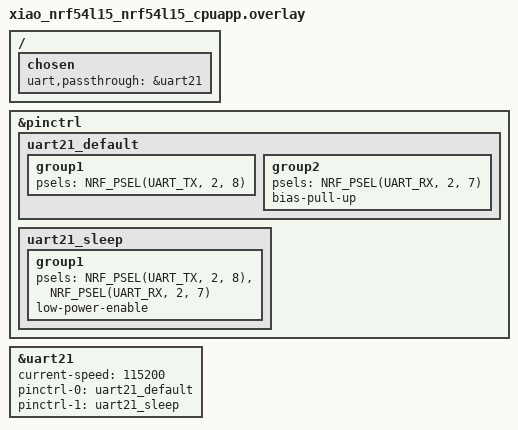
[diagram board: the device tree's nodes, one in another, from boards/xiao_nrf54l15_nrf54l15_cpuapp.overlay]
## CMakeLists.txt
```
# SPDX-License-Identifier: Apache-2.0

cmake_minimum_required(VERSION 3.20)

find_package(Zephyr REQUIRED HINTS $ENV{ZEPHYR_BASE})
project(xiao_nrf54l15_uart_test)

target_sources(app PRIVATE src/main.c)
```

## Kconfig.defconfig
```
# Fix for xiao_nrf54l15 BT_CTLR Kconfig warning
# The board's Kconfig.defconfig defines BT_CTLR without a type.
# This file is loaded before the board's defconfig, so we can properly define it here.

if BOARD_XIAO_NRF54L15_NRF54L15_CPUAPP

# Properly define BT_CTLR with type before the board's defconfig loads
config BT_CTLR
	bool
	default BT

endif
```

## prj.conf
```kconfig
# CONFIG_UART_INTERRUPT_DRIVEN=y

# CONFIG_SERIAL=y
```

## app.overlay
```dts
/ {
	chosen {
		ncs,dtm-uart = &uart20;
	};
};

/* uart20 is USB CDC, already configured in board dts with status = "okay" */
```

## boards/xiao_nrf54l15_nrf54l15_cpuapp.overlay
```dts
/*
 * XIAO nRF54L15 UART21 设备树配置
 *
 * 引脚:
 *   TX: P2.08 (D6)
 *   RX: P2.07 (D7)
 */

/ {
	chosen {
		uart,passthrough = &uart21;
	};
};

&pinctrl {
	uart21_default: uart21_default {
		group1 {
			psels = <NRF_PSEL(UART_TX, 2, 8)>;
		};
		group2 {
			psels = <NRF_PSEL(UART_RX, 2, 7)>;
			bias-pull-up;
		};
	};

	uart21_sleep: uart21_sleep {
		group1 {
			psels = <NRF_PSEL(UART_TX, 2, 8)>,
				<NRF_PSEL(UART_RX, 2, 7)>;
			low-power-enable;
		};
	};
};

&uart21 {
	current-speed = <115200>;
	pinctrl-0 = <&uart21_default>;
	pinctrl-1 = <&uart21_sleep>;
	pinctrl-names = "default", "sleep";
	status = "okay";
};
```

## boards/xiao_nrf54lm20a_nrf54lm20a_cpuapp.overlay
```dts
/*
 * Copyright (c) 2026
 *
 * SPDX-License-Identifier: LicenseRef-Nordic-5-Clause
 */

/ {
	chosen {
		ncs,dtm-uart = &uart20;
	};
};

&radio {
	/* XIAO board configuration does not provide the antenna matrix
	 * properties required by the DTM direction finding path.
	 */
	/delete-property/ dfe-supported;
};
```

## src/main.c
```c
/**
 * @file main.c
 * @brief BMM150 磁力计数据通过 ESP8266 MQTT 上传到 OneNET
 * STM32F103C8T6 @ 72MHz (HAL库)
 */

#include "stm32f1xx_hal.h"
#include "esp8266.h"
#include "onenet.h"
#include "mqttkit.h"
#include "bmm150.h"
#include "bmm150_platform.h"
#include "gps.h"
#include <stdio.h>
#include <string.h>

/* I2C和UART句柄 */
I2C_HandleTypeDef hi2c1;
UART_HandleTypeDef huart1;
UART_HandleTypeDef huart2;
UART_HandleTypeDef huart3;

/* ESP8266接收缓冲区 */
unsigned char esp8266_buf[512];
unsigned short esp8266_cnt = 0;

/* BMM150设备句柄和数据 */
bmm150_dev_t bmm150_dev;
bmm150_data_t bmm150_data;

/* BMM150全局数据 - 供onenet.c通过extern引用 */
int16_t bmm_x = 0;
int16_t bmm_y = 0;
int16_t bmm_z = 0;

/* 72MHz时钟配置 */
void SystemClock_Config(void)
{
    RCC_OscInitTypeDef osc = {0};
    RCC_ClkInitTypeDef clk = {0};

    osc.OscillatorType = RCC_OSCILLATORTYPE_HSE;
    osc.HSEState = RCC_HSE_ON;
    osc.PLL.PLLState = RCC_PLL_ON;
    osc.PLL.PLLSource = RCC_PLLSOURCE_HSE;
    osc.PLL.PLLMUL = RCC_PLL_MUL9;
    HAL_RCC_OscConfig(&osc);

    clk.ClockType = RCC_CLOCKTYPE_HCLK | RCC_CLOCKTYPE_SYSCLK |
                    RCC_CLOCKTYPE_PCLK1 | RCC_CLOCKTYPE_PCLK2;
    clk.SYSCLKSource = RCC_SYSCLKSOURCE_PLLCLK;
    clk.AHBCLKDivider = RCC_SYSCLK_DIV1;
    clk.APB1CLKDivider = RCC_HCLK_DIV2;
    clk.APB2CLKDivider = RCC_HCLK_DIV1;
    HAL_RCC_ClockConfig(&clk, FLASH_LATENCY_2);
}

/* USART1初始化 (调试输出) - PA9 TX, PA10 RX */
void USART1_Init(void)
{
    __HAL_RCC_USART1_CLK_ENABLE();
    __HAL_RCC_GPIOA_CLK_ENABLE();

    GPIO_InitTypeDef gpio = {0};

    /* PA9 TX */
    gpio.Pin = GPIO_PIN_9;
    gpio.Mode = GPIO_MODE_AF_PP;
    gpio.Speed = GPIO_SPEED_FREQ_HIGH;
    HAL_GPIO_Init(GPIOA, &gpio);

    /* PA10 RX */
    gpio.Pin = GPIO_PIN_10;
    gpio.Mode = GPIO_MODE_INPUT;
    gpio.Pull = GPIO_PULLUP;
    HAL_GPIO_Init(GPIOA, &gpio);

    /* 使用HAL库初始化USART1 */
    huart1.Instance = USART1;
    huart1.Init.BaudRate = 115200;
    huart1.Init.WordLength = UART_WORDLENGTH_8B;
    huart1.Init.StopBits = UART_STOPBITS_1;
    huart1.Init.Parity = UART_PARITY_NONE;
    huart1.Init.Mode = UART_MODE_TX_RX;
    huart1.Init.HwFlowCtl = UART_HWCONTROL_NONE;
    huart1.Init.OverSampling = UART_OVERSAMPLING_16;
    HAL_UART_Init(&huart1);
}

/* USART2初始化 (ESP8266通信) */
void USART2_Init(void)
{
    __HAL_RCC_USART2_CLK_ENABLE();
    __HAL_RCC_GPIOA_CLK_ENABLE();

    GPIO_InitTypeDef gpio = {0};
    gpio.Pin = GPIO_PIN_2;  /* TX */
    gpio.Mode = GPIO_MODE_AF_PP;
    gpio.Speed = GPIO_SPEED_FREQ_HIGH;
    HAL_GPIO_Init(GPIOA, &gpio);

    gpio.Pin = GPIO_PIN_3;  /* RX */
    gpio.Mode = GPIO_MODE_INPUT;
    gpio.Pull = GPIO_PULLUP;
    HAL_GPIO_Init(GPIOA, &gpio);

    huart2.Instance = USART2;
    huart2.Init.BaudRate = 115200;
    huart2.Init.WordLength = UART_WORDLENGTH_8B;
    huart2.Init.StopBits = UART_STOPBITS_1;
    huart2.Init.Parity = UART_PARITY_NONE;
    huart2.Init.Mode = UART_MODE_TX_RX;
    huart2.Init.HwFlowCtl = UART_HWCONTROL_NONE;
    huart2.Init.OverSampling = UART_OVERSAMPLING_16;
    HAL_UART_Init(&huart2);

    HAL_NVIC_SetPriority(USART2_IRQn, 0, 0);
    HAL_NVIC_EnableIRQ(USART2_IRQn);
    __HAL_UART_ENABLE_IT(&huart2, UART_IT_RXNE);
}

/* USART2中断接收 (ESP8266) */
void USART2_IRQHandler(void)
{
    if(__HAL_UART_GET_FLAG(&huart2, UART_FLAG_RXNE) != RESET)
    {
        if(esp8266_cnt >= sizeof(esp8266_buf))
            esp8266_cnt = 0;

        esp8266_buf[esp8266_cnt++] = (uint8_t)(huart2.Instance->DR & 0xFF);
        __HAL_UART_CLEAR_FLAG(&huart2, UART_FLAG_RXNE);
    }
}

/* I2C1初始化 (BMM150通信) - PB6 SCL, PB7 SDA */
void I2C1_Init(void)
{
    __HAL_RCC_I2C1_CLK_ENABLE();
    __HAL_RCC_GPIOB_CLK_ENABLE();

    GPIO_InitTypeDef gpio = {0};

    /* PB6 SCL, PB7 SDA */
    gpio.Pin = GPIO_PIN_6 | GPIO_PIN_7;
    gpio.Mode = GPIO_MODE_AF_OD;
    gpio.Speed = GPIO_SPEED_FREQ_HIGH;
    gpio.Pull = GPIO_PULLUP;
    HAL_GPIO_Init(GPIOB, &gpio);

    /* I2C1配置 */
    hi2c1.Instance = I2C1;
    hi2c1.Init.ClockSpeed = 100000;  /* 100kHz */
    hi2c1.Init.DutyCycle = I2C_DUTYCYCLE_2;
    hi2c1.Init.OwnAddress1 = 0;
    hi2c1.Init.AddressingMode = I2C_ADDRESSINGMODE_7BIT;
    hi2c1.Init.DualAddressMode = I2C_DUALADDRESS_DISABLE;
    hi2c1.Init.OwnAddress2 = 0;
    hi2c1.Init.GeneralCallMode = I2C_GENERALCALL_DISABLE;
    hi2c1.Init.NoStretchMode = I2C_NOSTRETCH_DISABLE;
    HAL_I2C_Init(&hi2c1);
}

/* I2C总线扫描 - 查找连接的设备 */
void I2C_Scan(void)
{
    char buf[50];
    UART1_SendString("Scanning I2C bus...\r\n");

    for (uint8_t addr = 0; addr < 128; addr++) {
        if (HAL_I2C_IsDeviceReady(&hi2c1, (uint16_t)(addr << 1), 1, 10) == HAL_OK) {
            sprintf(buf, "Found device at 0x%02X (7-bit: 0x%02X)\r\n", addr << 1, addr);
            UART1_SendString(buf);
        }
    }
    UART1_SendString("Scan complete.\r\n");
}

/* 简单串口发送函数 */
void UART1_SendString(const char *str)
{
    HAL_UART_Transmit(&huart1, (uint8_t*)str, strlen(str), 1000);
}

/* 全局调试打印函数 - 供其他模块调用 */
void DebugPrint(const char *str)
{
    UART1_SendString(str);
}

int main(void)
{
    HAL_Init();
    SystemClock_Config();

    /* LED PC13 */
    __HAL_RCC_GPIOC_CLK_ENABLE();
    GPIO_InitTypeDef led = {0};
    led.Pin = GPIO_PIN_13;
    led.Mode = GPIO_MODE_OUTPUT_PP;
    led.Speed = GPIO_SPEED_FREQ_LOW;
    HAL_GPIO_Init(GPIOC, &led);

    /* 初始化USART1 */
    USART1_Init();

    /* 立即发送测试数据 - 不依赖其他初始化 */
    UART1_SendString("USART1 Test OK!\r\n");
    HAL_Delay(100);
    UART1_SendString("System Init...\r\n");
    HAL_Delay(100);

    /* 初始化USART2 */
    USART2_Init();
    UART1_SendString("USART2 Init OK\r\n");

    /* 初始化I2C1 */
    I2C1_Init();
    UART1_SendString("I2C1 Init OK\r\n");

    /* 初始化GPS */
    GPS_Init();
    UART1_SendString("GPS Init OK\r\n");

    /* 扫描I2C总线，查找BMM150 */
    I2C_Scan();

    /* 初始化BMM150 */
    char msg_buf[100];
    UART1_SendString("Initializing BMM150...\r\n");

    /* 步骤1: 唤醒BMM150 - 写入0x01到电源控制寄存器0x4B */
    uint8_t pwr_cmd = 0x01;
    HAL_I2C_Mem_Write(&hi2c1, (BMM150_DEFAULT_I2C_ADDRESS << 1), 0x4B, I2C_MEMADD_SIZE_8BIT, &pwr_cmd, 1, 100);
    HAL_Delay(10);  /* 等待唤醒 */

    /* 步骤2: 再次读取Chip ID */
    uint8_t chip_id = 0;
    HAL_I2C_Mem_Read(&hi2c1, (BMM150_DEFAULT_I2C_ADDRESS << 1), 0x40, I2C_MEMADD_SIZE_8BIT, &chip_id, 1, 100);
    sprintf(msg_buf, "Chip ID after wake: 0x%02X (expected: 0x32)\r\n", chip_id);
    UART1_SendString(msg_buf);

    bmm150_status_t status = bmm150_init(&bmm150_dev, BMM150_DEFAULT_I2C_ADDRESS);
    if (status != BMM150_OK) {
        sprintf(msg_buf, "BMM150 Init FAILED! Error: %d\r\n", status);
        UART1_SendString(msg_buf);
        while (1) {
            HAL_GPIO_TogglePin(GPIOC, GPIO_PIN_13);
            HAL_Delay(100);
        }
    }
    UART1_SendString("BMM150 Init OK\r\n");

    UART1_SendString("\r\n=================================\r\n");
    UART1_SendString("STM32F103C8T6 @ 72MHz\r\n");
    UART1_SendString("BMM150 + ESP8266 MQTT\r\n");
    UART1_SendString("=================================\r\n\r\n");

    /* 初始化ESP8266并连接MQTT */
    UART1_SendString("Initializing ESP8266...\r\n");
    ESP8266_Init();

    UART1_SendString("\r\nConnecting to MQTT...\r\n");
    if (OneNet_DevLink() != 0) {
        UART1_SendString("MQTT Connect FAILED!\r\n");
        while (1) {
            HAL_GPIO_TogglePin(GPIOC, GPIO_PIN_13);
            HAL_Delay(100);
        }
    }

    /* 订阅主题 */
    OneNET_Subscribe();

    UART1_SendString("\r\nStart reading BMM150 sensor data...\r\n\r\n");

    uint32_t count = 0;

    while (1) {
        /* 从BMM150读取真实传感器数据 */
        status = bmm150_get_mag_data(&bmm150_dev, &bmm150_data);
        if (status == BMM150_OK) {
            bmm_x = (int16_t)bmm150_data.x;
            bmm_y = (int16_t)bmm150_data.y;
            bmm_z = (int16_t)bmm150_data.z;

            sprintf(msg_buf, "[%lu] X:%d Y:%d Z:%d (%.1f %.1f %.1f uT)\r\n",
                    count, bmm_x, bmm_y, bmm_z,
                    bmm150_data.x_uT, bmm150_data.y_uT, bmm150_data.z_uT);
            UART1_SendString(msg_buf);
        } else {
            sprintf(msg_buf, "[%lu] BMM150 read error: %d\r\n", count, status);
            UART1_SendString(msg_buf);
        }

        /* 显示GPS数据 */
        gps_data_t *gps = GPS_GetData();
        sprintf(msg_buf, "GPS: lat=%ld, lon=%ld, sats=%d, valid=%d\r\n",
                gps->latitude, gps->longitude, gps->sat_count, gps->valid);
        UART1_SendString(msg_buf);

        /* 发送到MQTT */
        OneNet_SendData();

        /* LED闪烁 */
        HAL_GPIO_TogglePin(GPIOC, GPIO_PIN_13);
        count++;

        /* 检查接收数据 */
        unsigned char *dataPtr = ESP8266_GetIPD(50);
        if (dataPtr != NULL) {
            OneNet_RevPro(dataPtr);
        }

        /* 定时发送心跳 */
        if (count % 30 == 0) {
            MQTT_Ping();
        }

        HAL_Delay(1000);
    }
}
```

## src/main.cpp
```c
#include <Arduino.h>

// PB02: Control pin - pull HIGH to enable voltage reading
// PB03: ADC input (AIN11)
// Reference: INTVCC1 (VDDANA/2), Gain: DIV2 -> Full scale = 3.3V

#define ADC_FULL_SCALE 4095.0f

static void adc_init(void) {
    // Enable ADC bus clock
    PM->APBCMASK.reg |= PM_APBCMASK_ADC;

    // Feed GCLK0 to ADC
    GCLK->CLKCTRL.reg = GCLK_CLKCTRL_ID_ADC |
                         GCLK_CLKCTRL_GEN_GCLK0 |
                         GCLK_CLKCTRL_CLKEN;
    while (GCLK->STATUS.bit.SYNCBUSY);

    // Reset ADC
    ADC->CTRLA.bit.SWRST = 1;
    while (ADC->CTRLA.bit.SWRST);

    // Reference: INTVCC1 = VDDANA / 2 (~1.65V)
    ADC->REFCTRL.reg = ADC_REFCTRL_REFSEL_INTVCC1;

    // No averaging
    ADC->AVGCTRL.reg = ADC_AVGCTRL_SAMPLENUM_1;

    // 12-bit resolution, prescaler DIV32 (48MHz/32 = 1.5MHz)
    ADC->CTRLB.reg = ADC_CTRLB_RESSEL_12BIT |
                     ADC_CTRLB_PRESCALER_DIV32;
    while (ADC->STATUS.bit.SYNCBUSY);

    // Positive input: AIN11 (PB03), Negative: GND, Gain: DIV2
    // DIV2 gain + 1.65V ref = 3.3V full scale
    ADC->INPUTCTRL.reg = ADC_INPUTCTRL_MUXPOS_PIN11 |
                         ADC_INPUTCTRL_MUXNEG_GND |
                         ADC_INPUTCTRL_GAIN_DIV2;
    while (ADC->STATUS.bit.SYNCBUSY);

    // Enable ADC
    ADC->CTRLA.bit.ENABLE = 1;
    while (ADC->STATUS.bit.SYNCBUSY);
}

static uint16_t adc_read(void) {
    ADC->SWTRIG.bit.START = 1;
    while (ADC->STATUS.bit.SYNCBUSY);
    while (!ADC->INTFLAG.bit.RESRDY);
    return ADC->RESULT.reg;
}

void setup() {
    Serial1.begin(230400);
    delay(100);

    Serial1.println("============================================");
    Serial1.println("  ADC Voltage Reader - XIAO SAMD21");
    Serial1.println("  ADC Pin: PB03 (AIN11)");
    Serial1.println("  Control: PB02 (HIGH to enable reading)");
    Serial1.println("============================================");

    // PB02: GPIO output, pull HIGH and keep
    PORT->Group[1].DIRSET.reg = PORT_PB02;
    PORT->Group[1].OUTSET.reg = PORT_PB02;
    delay(1);  // Wait for voltage to settle

    // PB03: analog input via peripheral mux
    PORT->Group[1].PINCFG[3].bit.PMUXEN = 1;   // Enable PMUX
    PORT->Group[1].PINCFG[3].bit.INEN   = 0;   // Disable digital input buffer
    PORT->Group[1].PINCFG[3].bit.PULLEN = 0;   // No pull resistor
    // PB03 is odd pin -> uses PMUX[1].PMUXO, function B = Analog
    PORT->Group[1].PMUX[1].bit.PMUXO = PORT_PMUX_PMUXO_B_Val;

    adc_init();
    Serial1.println("ADC initialized, starting readings...\n");
}

void loop() {
    uint16_t raw = adc_read();

    // Voltage = raw * (1.65V * 2) / 4095 = raw * 3.3 / 4095
    float voltage = (raw * 3.3f) / ADC_FULL_SCALE;

    Serial1.print("Raw: ");
    Serial1.print(raw);
    Serial1.print("  Voltage: ");
    Serial1.print(voltage, 3);
    Serial1.println(" V");

    delay(1000);
}
```

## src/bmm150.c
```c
/**
 * @file bmm150.c
 * @brief BMM150 三轴地磁传感器驱动实现
 */

#include <stdint.h>
#include <stddef.h>
#include "bmm150.h"
#include "bmm150_platform.h"

/* 校准数据掩码和位置 */
#define BMM150_TRIM_XLSB_MASK       0x7F
#define BMM150_TRIM_YLSB_MASK       0x7F
#define BMM150_TRIM_ZLSB_MASK       0x7F
#define BMM150_TRIM_XYLSB_SHIFT     7

/* 校准系数 */
#define BMM150_LSB_TO_UT_FACTOR     16.0f   /* LSB到微特斯拉转换因子 */

/* 内部函数声明 */
static bmm150_status_t read_trim_data(bmm150_dev_t *dev);
static int16_t compensate_x(int16_t raw_x, bmm150_dev_t *dev);
static int16_t compensate_y(int16_t raw_y, bmm150_dev_t *dev);
static int16_t compensate_z(int16_t raw_z, bmm150_dev_t *dev);

/**
 * @brief 初始化BMM150传感器
 */
bmm150_status_t bmm150_init(bmm150_dev_t *dev, uint8_t i2c_addr)
{
    uint8_t chip_id = 0;
    bmm150_status_t status;

    if (dev == NULL) {
        return BMM150_E_NULL_PTR;
    }

    dev->i2c_addr = i2c_addr;

    /* 检查设备是否存在 */
    status = bmm150_get_chip_id(dev, &chip_id);
    if (status != BMM150_OK) {
        return status;
    }

    if (chip_id != BMM150_CHIP_ID) {
        return BMM150_E_DEV_NOT_FOUND;
    }

    /* 设置默认配置 - 不执行软复位，直接配置 */
    dev->config.op_mode = BMM150_NORMAL_MODE;
    dev->config.data_rate = BMM150_DATA_RATE_10HZ;
    dev->config.xy_rep = BMM150_REPXY_REGULAR;
    dev->config.z_rep = BMM150_REPZ_REGULAR;

    /* 写入默认配置 */
    bmm150_set_data_rate(dev, dev->config.data_rate);
    bmm150_set_xy_rep(dev, dev->config.xy_rep);
    bmm150_set_z_rep(dev, dev->config.z_rep);
    bmm150_set_op_mode(dev, dev->config.op_mode);

    /* 读取校准数据 */
    status = read_trim_data(dev);
    if (status != BMM150_OK) {
        return status;
    }

    return BMM150_OK;
}

/**
 * @brief 软复位传感器
 */
bmm150_status_t bmm150_soft_reset(bmm150_dev_t *dev)
{
    uint8_t reg_data;
    bmm150_status_t status;

    if (dev == NULL) {
        return BMM150_E_NULL_PTR;
    }

    /* 写入软复位命令 */
    reg_data = BMM150_POWER_CNTRL_SOFT_RESET;
    status = bmm150_write_reg(dev, BMM150_POWER_CONTROL_REG, &reg_data, 1);
    if (status != BMM150_OK) {
        return status;
    }

    /* 等待复位完成 */
    bmm150_delay_ms(2);

    /* 检查复位是否完成 */
    do {
        status = bmm150_read_reg(dev, BMM150_POWER_CONTROL_REG, &reg_data, 1);
        if (status != BMM150_OK) {
            return status;
        }
    } while (reg_data & BMM150_POWER_CNTRL_SOFT_RESET);

    return BMM150_OK;
}

/**
 * @brief 设置操作模式
 */
bmm150_status_t bmm150_set_op_mode(bmm150_dev_t *dev, uint8_t op_mode)
{
    uint8_t reg_data;
    bmm150_status_t status;

    if (dev == NULL) {
        return BMM150_E_NULL_PTR;
    }

    status = bmm150_read_reg(dev, BMM150_OP_MODE_REG, &reg_data, 1);
    if (status != BMM150_OK) {
        return status;
    }

    reg_data = (reg_data & 0xE1) | (op_mode & 0x1E);

    status = bmm150_write_reg(dev, BMM150_OP_MODE_REG, &reg_data, 1);
    if (status == BMM150_OK) {
        dev->config.op_mode = op_mode;
    }

    return status;
}

/**
 * @brief 设置数据输出速率
 */
bmm150_status_t bmm150_set_data_rate(bmm150_dev_t *dev, uint8_t data_rate)
{
    uint8_t reg_data;
    bmm150_status_t status;

    if (dev == NULL) {
        return BMM150_E_NULL_PTR;
    }

    status = bmm150_read_reg(dev, BMM150_OP_MODE_REG, &reg_data, 1);
    if (status != BMM150_OK) {
        return status;
    }

    reg_data = (reg_data & 0x1F) | ((data_rate << 3) & 0xE0);

    status = bmm150_write_reg(dev, BMM150_OP_MODE_REG, &reg_data, 1);
    if (status == BMM150_OK) {
        dev->config.data_rate = data_rate;
    }

    return status;
}

/**
 * @brief 设置XY轴重复次数
 */
bmm150_status_t bmm150_set_xy_rep(bmm150_dev_t *dev, uint8_t rep_xy)
{
    bmm150_status_t status;

    if (dev == NULL) {
        return BMM150_E_NULL_PTR;
    }

    status = bmm150_write_reg(dev, BMM150_REP_XY_REG, &rep_xy, 1);
    if (status == BMM150_OK) {
        dev->config.xy_rep = rep_xy;
    }

    return status;
}

/**
 * @brief 设置Z轴重复次数
 */
bmm150_status_t bmm150_set_z_rep(bmm150_dev_t *dev, uint8_t rep_z)
{
    bmm150_status_t status;

    if (dev == NULL) {
        return BMM150_E_NULL_PTR;
    }

    status = bmm150_write_reg(dev, BMM150_REP_Z_REG, &rep_z, 1);
    if (status == BMM150_OK) {
        dev->config.z_rep = rep_z;
    }

    return status;
}

/**
 * @brief 检查数据是否就绪
 */
uint8_t bmm150_is_data_ready(bmm150_dev_t *dev)
{
    uint8_t reg_data;

    if (dev == NULL) {
        return 0;
    }

    if (bmm150_read_reg(dev, BMM150_DATA_READY_STATUS, &reg_data, 1) != BMM150_OK) {
        return 0;
    }

    return (reg_data & 0x01);
}

/**
 * @brief 获取原始磁力数据
 */
bmm150_status_t bmm150_get_raw_data(bmm150_dev_t *dev, bmm150_data_t *data)
{
    uint8_t buffer[8];
    bmm150_status_t status;

    if (dev == NULL || data == NULL) {
        return BMM150_E_NULL_PTR;
    }

    /* 如果是强制模式，需要先触发测量 */
    if (dev->config.op_mode == BMM150_FORCED_MODE) {
        status = bmm150_set_op_mode(dev, BMM150_FORCED_MODE);
        if (status != BMM150_OK) {
            return status;
        }
        /* 等待数据就绪 */
        while (!bmm150_is_data_ready(dev)) {
            bmm150_delay_ms(1);
        }
    }

    /* 读取数据寄存器 (0x42-0x48) */
    status = bmm150_read_reg(dev, BMM150_DATA_X_LSB, buffer, 8);
    if (status != BMM150_OK) {
        return status;
    }

    /* 解析X轴数据 (13位, 有符号) */
    data->x = (int16_t)(((uint16_t)buffer[1] << 8) | (buffer[0] & 0xF8));
    data->x = data->x >> 3;

    /* 解析Y轴数据 (13位, 有符号) */
    data->y = (int16_t)(((uint16_t)buffer[3] << 8) | (buffer[2] & 0xF8));
    data->y = data->y >> 3;

    /* 解析Z轴数据 (15位, 有符号) */
    data->z = (int16_t)(((uint16_t)buffer[5] << 8) | (buffer[4] & 0xFE));
    data->z = data->z >> 1;

    /* 数据就绪状态 */
    data->data_ready = buffer[7] & 0x01;

    return BMM150_OK;
}

/**
 * @brief 获取转换后的磁力数据(微特斯拉)
 */
bmm150_status_t bmm150_get_mag_data(bmm150_dev_t *dev, bmm150_data_t *data)
{
    bmm150_status_t status;
    int16_t compensated_x, compensated_y, compensated_z;

    if (dev == NULL || data == NULL) {
        return BMM150_E_NULL_PTR;
    }

    /* 获取原始数据 */
    status = bmm150_get_raw_data(dev, data);
    if (status != BMM150_OK) {
        return status;
    }

    /* 应用补偿 */
    compensated_x = compensate_x(data->x, dev);
    compensated_y = compensate_y(data->y, dev);
    compensated_z = compensate_z(data->z, dev);

    /* 转换为微特斯拉 */
    data->x_uT = (float)compensated_x * BMM150_LSB_TO_UT_FACTOR / 1000.0f;
    data->y_uT = (float)compensated_y * BMM150_LSB_TO_UT_FACTOR / 1000.0f;
    data->z_uT = (float)compensated_z * BMM150_LSB_TO_UT_FACTOR / 1000.0f;

    return BMM150_OK;
}

/**
 * @brief 读取芯片ID
 */
bmm150_status_t bmm150_get_chip_id(bmm150_dev_t *dev, uint8_t *chip_id)
{
    if (dev == NULL || chip_id == NULL) {
        return BMM150_E_NULL_PTR;
    }

    return bmm150_read_reg(dev, BMM150_CHIP_ID_REG, chip_id, 1);
}

/**
 * @brief 执行自检
 */
bmm150_status_t bmm150_self_test(bmm150_dev_t *dev)
{
    uint8_t reg_data;
    bmm150_status_t status;

    if (dev == NULL) {
        return BMM150_E_NULL_PTR;
    }

    /* 进入睡眠模式 */
    status = bmm150_set_op_mode(dev, BMM150_SLEEP_MODE);
    if (status != BMM150_OK) {
        return status;
    }

    bmm150_delay_ms(3);

    /* 启用自检 */
    reg_data = 0x01;
    status = bmm150_write_reg(dev, BMM150_BIST_CTRL_REG, &reg_data, 1);
    if (status != BMM150_OK) {
        return status;
    }

    bmm150_delay_ms(10);

    /* 检查自检结果 */
    status = bmm150_read_reg(dev, BMM150_BIST_STATUS_REG, &reg_data, 1);
    if (status != BMM150_OK) {
        return status;
    }

    /* 清除自检设置 */
    reg_data = 0x00;
    bmm150_write_reg(dev, BMM150_BIST_CTRL_REG, &reg_data, 1);

    /* 检查自检是否通过 */
    if (reg_data & 0x01) {
        return BMM150_OK;
    }

    return BMM150_E_SELF_TEST_FAIL;
}

/* ==================== 内部函数实现 ==================== */

/**
 * @brief 读取校准数据
 */
static bmm150_status_t read_trim_data(bmm150_dev_t *dev)
{
    uint8_t trim_xlsb, trim_xmsb;
    uint8_t trim_ylsb, trim_ymsb;
    uint8_t trim_zlsb, trim_zmsb;
    uint8_t trim_xy1_xy2;
    bmm150_status_t status;

    /* 读取X轴校准数据 */
    status = bmm150_read_reg(dev, BMM150_TRIM_XLSB_REG, &trim_xlsb, 1);
    if (status != BMM150_OK) return status;

    status = bmm150_read_reg(dev, BMM150_TRIM_XMSB_REG, &trim_xmsb, 1);
    if (status != BMM150_OK) return status;

    /* 读取Y轴校准数据 */
    status = bmm150_read_reg(dev, BMM150_TRIM_YLSB_REG, &trim_ylsb, 1);
    if (status != BMM150_OK) return status;

    status = bmm150_read_reg(dev, BMM150_TRIM_YMSB_REG, &trim_ymsb, 1);
    if (status != BMM150_OK) return status;

    /* 读取Z轴校准数据 */
    status = bmm150_read_reg(dev, BMM150_TRIM_ZLSB_REG, &trim_zlsb, 1);
    if (status != BMM150_OK) return status;

    status = bmm150_read_reg(dev, BMM150_TRIM_ZMSB_REG, &trim_zmsb, 1);
    if (status != BMM150_OK) return status;

    /* 读取XY校准数据 */
    status = bmm150_read_reg(dev, BMM150_TRIM_DATA_REG, &trim_xy1_xy2, 1);
    if (status != BMM150_OK) return status;

    /* 组合校准数据 */
    dev->trim_data[0] = (int16_t)((trim_xmsb << 8) | (trim_xlsb & BMM150_TRIM_XLSB_MASK));
    dev->trim_data[1] = (int16_t)((trim_ymsb << 8) | (trim_ylsb & BMM150_TRIM_YLSB_MASK));
    dev->trim_data[2] = (int16_t)((trim_zmsb << 8) | (trim_zlsb & BMM150_TRIM_ZLSB_MASK));
    dev->trim_data[3] = (int16_t)trim_xy1_xy2;

    return BMM150_OK;
}

/**
 * @brief X轴数据补偿
 */
static int16_t compensate_x(int16_t raw_x, bmm150_dev_t *dev)
{
    int16_t compensated_x;
    int16_t trim_x = dev->trim_data[0];
    uint16_t trim_xy1 = dev->trim_data[3] & 0x7F;
    uint16_t trim_xy2 = (dev->trim_data[3] >> 7) & 0x01;

    /* 简化的补偿算法 */
    compensated_x = raw_x - trim_x;

    /* 修正补偿 (BMM150数据手册中的补偿公式) */
    if (trim_xy1 != 0) {
        compensated_x = compensated_x + (int16_t)((trim_xy1 << 1) * (trim_xy2 ? 1 : -1));
    }

    return compensated_x;
}

/**
 * @brief Y轴数据补偿
 */
static int16_t compensate_y(int16_t raw_y, bmm150_dev_t *dev)
{
    int16_t compensated_y;
    int16_t trim_y = dev->trim_data[1];
    uint16_t trim_xy1 = dev->trim_data[3] & 0x7F;
    uint16_t trim_xy2 = (dev->trim_data[3] >> 7) & 0x01;

    /* 简化的补偿算法 */
    compensated_y = raw_y - trim_y;

    /* 修正补偿 */
    if (trim_xy1 != 0) {
        compensated_y = compensated_y + (int16_t)((trim_xy1 << 1) * (trim_xy2 ? -1 : 1));
    }

    return compensated_y;
}

/**
 * @brief Z轴数据补偿
 */
static int16_t compensate_z(int16_t raw_z, bmm150_dev_t *dev)
{
    int16_t compensated_z;
    int16_t trim_z = dev->trim_data[2];

    /* Z轴补偿 */
    compensated_z = raw_z - trim_z;

    return compensated_z;
}
```

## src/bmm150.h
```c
/**
 * @file bmm150.h
 * @brief BMM150 三轴地磁传感器驱动
 * @note 适用于 STM32F103C8T6
 */

#ifndef __BMM150_H
#define __BMM150_H

#ifdef __cplusplus
extern "C" {
#endif

#include <stdint.h>

/* BMM150 I2C 地址 (7位地址) */
#define BMM150_DEFAULT_I2C_ADDRESS     0x13    /* 默认I2C地址 */
#define BMM150_I2C_ADDRESS_2           0x14    /* 替代I2C地址 */

/* BMM150 寄存器地址 */
#define BMM150_CHIP_ID_REG             0x40
#define BMM150_DATA_X_LSB              0x42
#define BMM150_DATA_X_MSB              0x43
#define BMM150_DATA_Y_LSB              0x44
#define BMM150_DATA_Y_MSB              0x45
#define BMM150_DATA_Z_LSB              0x46
#define BMM150_DATA_Z_MSB              0x47
#define BMM150_DATA_READY_STATUS       0x48
#define BMM150_INTERRUPT_STATUS         0x4A
#define BMM150_POWER_CONTROL_REG        0x4B
#define BMM150_OP_MODE_REG              0x4C
#define BMM150_INT_CONFIG_REG           0x4D
#define BMM150_AXES_ENABLE_REG          0x4E
#define BMM150_LOW_THRES_INT_REG        0x4F
#define BMM150_HIGH_THRES_INT_REG       0x50
#define BMM150_REP_XY_REG               0x51
#define BMM150_REP_Z_REG                0x52
#define BMM150_TRIM_XLSB_REG            0x5D
#define BMM150_TRIM_XMSB_REG            0x5E
#define BMM150_TRIM_YLSB_REG            0x5F
#define BMM150_TRIM_YMSB_REG            0x60
#define BMM150_TRIM_ZLSB_REG            0x61
#define BMM150_TRIM_ZMSB_REG            0x62
#define BMM150_TRIM_DATA_REG            0x63
#define BMM150_BIST_CTRL_REG            0x64
#define BMM150_BIST_STATUS_REG          0x65

/* 芯片ID */
#define BMM150_CHIP_ID                  0x32

/* 电源控制位 */
#define BMM150_POWER_CNTRL_SOFT_RESET   0x80
#define BMM150_POWER_CNTRL_SRST_DONE     0x01
#define BMM150_POWER_CNTRL_MSK          0x01

/* 操作模式 */
#define BMM150_NORMAL_MODE              0x00
#define BMM150_FORCED_MODE             0x01
#define BMM150_SLEEP_MODE              0x03
#define BMM150_SUSPEND_MODE            0x04

/* 数据速率 (ODR) */
#define BMM150_DATA_RATE_10HZ          0x00
#define BMM150_DATA_RATE_02HZ          0x01
#define BMM150_DATA_RATE_06HZ          0x02
#define BMM150_DATA_RATE_08HZ          0x03
#define BMM150_DATA_RATE_15HZ          0x04
#define BMM150_DATA_RATE_20HZ          0x05
#define BMM150_DATA_RATE_25HZ          0x06
#define BMM150_DATA_RATE_30HZ          0x07

/* XY重复次数 (精度) */
#define BMM150_REPXY_LOWPOWER          0x01    /* 3次  */
#define BMM150_REPXY_REGULAR           0x04    /* 9次  */
#define BMM150_REPXY_ENHANCED          0x07    /* 15次 */
#define BMM150_REPXY_HIGHACCURACY      0x17    /* 47次 */

/* Z轴重复次数 (精度) */
#define BMM150_REPZ_LOWPOWER           0x01    /* 3次  */
#define BMM150_REPZ_REGULAR            0x0E    /* 14次 */
#define BMM150_REPZ_ENHANCED           0x1B    /* 27次 */
#define BMM150_REPZ_HIGHACCURACY       0x39    /* 57次 */

/* 状态返回值 */
typedef enum {
    BMM150_OK = 0,
    BMM150_E_NULL_PTR,
    BMM150_E_DEV_NOT_FOUND,
    BMM150_E_INVALID_ARG,
    BMM150_E_COMM_FAIL,
    BMM150_E_SELF_TEST_FAIL,
    BMM150_E_NOT_READY
} bmm150_status_t;

/* 传感器数据结构 */
typedef struct {
    int16_t x;          /* X轴原始数据 */
    int16_t y;          /* Y轴原始数据 */
    int16_t z;          /* Z轴原始数据 */
    float x_uT;         /* X轴微特斯拉 */
    float y_uT;         /* Y轴微特斯拉 */
    float z_uT;         /* Z轴微特斯拉 */
    uint16_t data_ready;/* 数据就绪标志 */
} bmm150_data_t;

/* 配置结构 */
typedef struct {
    uint8_t op_mode;    /* 操作模式 */
    uint8_t data_rate;  /* 数据输出速率 */
    uint8_t xy_rep;     /* XY轴重复次数 */
    uint8_t z_rep;      /* Z轴重复次数 */
} bmm150_config_t;

/* 设备句柄结构 */
typedef struct {
    uint8_t i2c_addr;
    int16_t trim_data[4];   /* 校准数据 */
    bmm150_config_t config;
} bmm150_dev_t;

/* 函数声明 */

/**
 * @brief 初始化BMM150传感器
 * @param dev 设备句柄
 * @param i2c_addr I2C地址
 * @return 状态码
 */
bmm150_status_t bmm150_init(bmm150_dev_t *dev, uint8_t i2c_addr);

/**
 * @brief 软复位传感器
 * @param dev 设备句柄
 * @return 状态码
 */
bmm150_status_t bmm150_soft_reset(bmm150_dev_t *dev);

/**
 * @brief 设置操作模式
 * @param dev 设备句柄
 * @param op_mode 操作模式
 * @return 状态码
 */
bmm150_status_t bmm150_set_op_mode(bmm150_dev_t *dev, uint8_t op_mode);

/**
 * @brief 设置数据输出速率
 * @param dev 设备句柄
 * @param data_rate 数据速率
 * @return 状态码
 */
bmm150_status_t bmm150_set_data_rate(bmm150_dev_t *dev, uint8_t data_rate);

/**
 * @brief 设置XY轴重复次数
 * @param dev 设备句柄
 * @param rep_xy 重复次数设置
 * @return 状态码
 */
bmm150_status_t bmm150_set_xy_rep(bmm150_dev_t *dev, uint8_t rep_xy);

/**
 * @brief 设置Z轴重复次数
 * @param dev 设备句柄
 * @param rep_z 重复次数设置
 * @return 状态码
 */
bmm150_status_t bmm150_set_z_rep(bmm150_dev_t *dev, uint8_t rep_z);

/**
 * @brief 获取原始磁力数据
 * @param dev 设备句柄
 * @param data 数据结构指针
 * @return 状态码
 */
bmm150_status_t bmm150_get_raw_data(bmm150_dev_t *dev, bmm150_data_t *data);

/**
 * @brief 获取转换后的磁力数据(微特斯拉)
 * @param dev 设备句柄
 * @param data 数据结构指针
 * @return 状态码
 */
bmm150_status_t bmm150_get_mag_data(bmm150_dev_t *dev, bmm150_data_t *data);

/**
 * @brief 检查数据是否就绪
 * @param dev 设备句柄
 * @return 1:就绪 0:未就绪
 */
uint8_t bmm150_is_data_ready(bmm150_dev_t *dev);

/**
 * @brief 执行自检
 * @param dev 设备句柄
 * @return 状态码
 */
bmm150_status_t bmm150_self_test(bmm150_dev_t *dev);

/**
 * @brief 读取芯片ID
 * @param dev 设备句柄
 * @param chip_id 芯片ID指针
 * @return 状态码
 */
bmm150_status_t bmm150_get_chip_id(bmm150_dev_t *dev, uint8_t *chip_id);

#ifdef __cplusplus
}
#endif

#endif /* __BMM150_H */
```

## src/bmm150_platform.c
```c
/**
 * @file bmm150_platform.c
 * @brief BMM150 平台抽象层实现 - STM32F103C8T6 HAL库
 */

#include "bmm150_platform.h"
#include "main.h"       /* STM32 HAL头文件 */

/* 外部变量声明 - 由CubeMX生成 */
extern I2C_HandleTypeDef hi2c1;

/**
 * @brief 读取寄存器
 */
bmm150_status_t bmm150_read_reg(bmm150_dev_t *dev, uint8_t reg_addr, uint8_t *data, uint16_t len)
{
    HAL_StatusTypeDef status;

    if (dev == NULL || data == NULL) {
        return BMM150_E_NULL_PTR;
    }

    status = HAL_I2C_Mem_Read(&hi2c1,
                              (uint16_t)(dev->i2c_addr << 1),
                              reg_addr,
                              I2C_MEMADD_SIZE_8BIT,
                              data,
                              len,
                              BMM150_I2C_TIMEOUT);

    if (status == HAL_OK) {
        return BMM150_OK;
    } else if (status == HAL_TIMEOUT) {
        return BMM150_E_NOT_READY;
    } else {
        return BMM150_E_COMM_FAIL;
    }
}

/**
 * @brief 写入寄存器
 */
bmm150_status_t bmm150_write_reg(bmm150_dev_t *dev, uint8_t reg_addr, uint8_t *data, uint16_t len)
{
    HAL_StatusTypeDef status;

    if (dev == NULL || data == NULL) {
        return BMM150_E_NULL_PTR;
    }

    status = HAL_I2C_Mem_Write(&hi2c1,
                               (uint16_t)(dev->i2c_addr << 1),
                               reg_addr,
                               I2C_MEMADD_SIZE_8BIT,
                               data,
                               len,
                               BMM150_I2C_TIMEOUT);

    if (status == HAL_OK) {
        return BMM150_OK;
    } else if (status == HAL_TIMEOUT) {
        return BMM150_E_NOT_READY;
    } else {
        return BMM150_E_COMM_FAIL;
    }
}

/**
 * @brief 毫秒级延时
 */
void bmm150_delay_ms(uint32_t ms)
{
    HAL_Delay(ms);
}
```

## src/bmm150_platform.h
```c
/**
 * @file bmm150_platform.h
 * @brief BMM150 平台抽象层 - STM32F103C8T6 I2C接口
 */

#ifndef __BMM150_PLATFORM_H
#define __BMM150_PLATFORM_H

#ifdef __cplusplus
extern "C" {
#endif

#include <stdint.h>
#include "bmm150.h"

/* 平台配置 - 根据你的硬件连接修改 */
#define BMM150_I2C_HANDLE       hi2c1       /* I2C句柄 */
#define BMM150_I2C_TIMEOUT      100         /* I2C超时(ms) */

/* 函数声明 - 需要用户实现 */

/**
 * @brief 读取寄存器
 * @param dev 设备句柄
 * @param reg_addr 寄存器地址
 * @param data 数据缓冲区
 * @param len 数据长度
 * @return 状态码
 */
bmm150_status_t bmm150_read_reg(bmm150_dev_t *dev, uint8_t reg_addr, uint8_t *data, uint16_t len);

/**
 * @brief 写入寄存器
 * @param dev 设备句柄
 * @param reg_addr 寄存器地址
 * @param data 数据缓冲区
 * @param len 数据长度
 * @return 状态码
 */
bmm150_status_t bmm150_write_reg(bmm150_dev_t *dev, uint8_t reg_addr, uint8_t *data, uint16_t len);

/**
 * @brief 毫秒级延时
 * @param ms 延时毫秒数
 */
void bmm150_delay_ms(uint32_t ms);

#ifdef __cplusplus
}
#endif

#endif /* __BMM150_PLATFORM_H */
```

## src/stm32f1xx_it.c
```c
/**
 * @file stm32f1xx_it.c
 * @brief Interrupt Handlers
 */

#include "main.h"
#include "stm32f1xx_it.h"

extern I2C_HandleTypeDef hi2c1;

void NMI_Handler(void)
{
}

void HardFault_Handler(void)
{
  while (1) {
  }
}

void MemManage_Handler(void)
{
  while (1) {
  }
}

void BusFault_Handler(void)
{
  while (1) {
  }
}

void UsageFault_Handler(void)
{
  while (1) {
  }
}

void SVC_Handler(void)
{
}

void DebugMon_Handler(void)
{
}

void PendSV_Handler(void)
{
}

void SysTick_Handler(void)
{
  HAL_IncTick();
}

void I2C1_EV_IRQHandler(void)
{
  HAL_I2C_EV_IRQHandler(&hi2c1);
}

void I2C1_ER_IRQHandler(void)
{
  HAL_I2C_ER_IRQHandler(&hi2c1);
}
```
